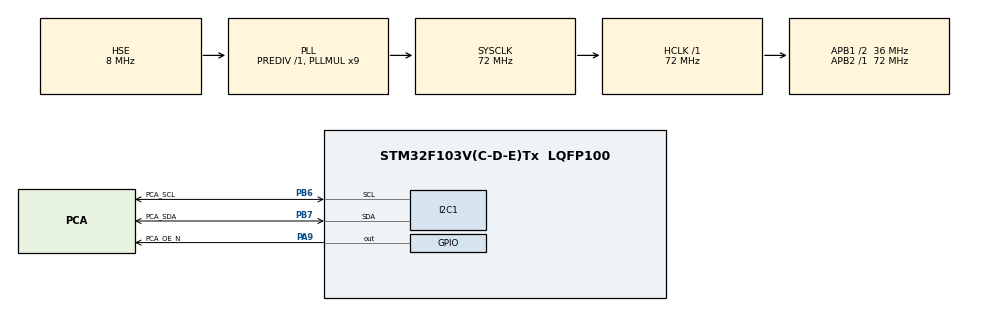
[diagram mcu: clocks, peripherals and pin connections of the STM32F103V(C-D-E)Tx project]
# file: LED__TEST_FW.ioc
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FREERTOS.BinarySemaphores01=allowRainbowSem,Dynamic,NULL
FREERTOS.Tasks01=initialSequence,0,256,initialSequenceTask,Default,NULL,Dynamic,NULL,NULL;rainbowTaskHand,-3,256,rainbowLoopTask,Default,NULL,Dynamic,NULL,NULL
FREERTOS.configUSE_NEWLIB_REENTRANT=1
Mcu.Family=STM32F1
Mcu.Name=STM32F103V(C-D-E)Tx
Mcu.Package=LQFP100
NVIC.I2C1_EV_IRQn=true\:5\:0\:false\:false\:true\:true\:true\:true\:true
NVIC.PriorityGroup=NVIC_PRIORITYGROUP_4
OSC_IN.Mode=HSE-External-Oscillator
OSC_IN.Signal=RCC_OSC_IN
OSC_OUT.Mode=HSE-External-Oscillator
OSC_OUT.Signal=RCC_OSC_OUT
PA13.Mode=Serial_Wire
PA13.Signal=SYS_JTMS-SWDIO
PA14.Mode=Serial_Wire
PA14.Signal=SYS_JTCK-SWCLK
PA9.GPIO_Label=PCA_OE_N
PA9.GPIO_PuPd=GPIO_PULLDOWN
PA9.Signal=GPIO_Output
PB6.GPIO_Label=PCA_SCL
PB6.Mode=I2C
PB6.Signal=I2C1_SCL
PB7.GPIO_Label=PCA_SDA
PB7.Mode=I2C
PB7.Signal=I2C1_SDA
ProjectManager.HeapSize=0x200
ProjectManager.StackSize=0x400
ProjectManager.TargetToolchain=STM32CubeIDE
RCC.AHBFreq_Value=72000000
RCC.APB1CLKDivider=RCC_HCLK_DIV2
RCC.APB1Freq_Value=36000000
RCC.APB1TimFreq_Value=72000000
RCC.APB2Freq_Value=72000000
RCC.APB2TimFreq_Value=72000000
RCC.HCLKFreq_Value=72000000
RCC.PLLMUL=RCC_PLL_MUL9
RCC.PLLSourceVirtual=RCC_PLLSOURCE_HSE
RCC.SYSCLKFreq_VALUE=72000000
RCC.SYSCLKSource=RCC_SYSCLKSOURCE_PLLCLK
RCC.USBFreq_Value=72000000
VP_FREERTOS_VS_CMSIS_V1.Mode=CMSIS_V1
board=custom

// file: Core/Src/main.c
/* USER CODE BEGIN Header */
/**
  ******************************************************************************
  * @file           : main.c
  * @brief          : Main program body
  ******************************************************************************
  * @attention
  *
  * Copyright (c) 2023 STMicroelectronics.
  * All rights reserved.
  *
  * This software is licensed under terms that can be found in the LICENSE file
  * in the root directory of this software component.
  * If no LICENSE file comes with this software, it is provided AS-IS.
  *
  ******************************************************************************
  */
/* USER CODE END Header */
#include "main.h"
#include "cmsis_os.h"
#include "i2c.h"
#include "gpio.h"

void SystemClock_Config(void);
void MX_FREERTOS_Init(void);

int main(void)
{

  /* MCU Configuration--------------------------------------------------------*/

  /* Reset of all peripherals, Initializes the Flash interface and the Systick. */
  HAL_Init();

  /* Configure the system clock */
  SystemClock_Config();

  /* Initialize all configured peripherals */
  MX_GPIO_Init();
  MX_I2C1_Init();

  /* Call init function for freertos objects (in freertos.c) */
  MX_FREERTOS_Init();

  /* Start scheduler */
  osKernelStart();

  /* We should never get here as control is now taken by the scheduler */
  /* Infinite loop */
  while (1)
  {

  }
}

void SystemClock_Config(void)
{
  RCC_OscInitTypeDef RCC_OscInitStruct = {0};
  RCC_ClkInitTypeDef RCC_ClkInitStruct = {0};

  /** Initializes the RCC Oscillators according to the specified parameters
  * in the RCC_OscInitTypeDef structure.
  */
  RCC_OscInitStruct.OscillatorType = RCC_OSCILLATORTYPE_HSE;
  RCC_OscInitStruct.HSEState = RCC_HSE_ON;
  RCC_OscInitStruct.HSEPredivValue = RCC_HSE_PREDIV_DIV1;
  RCC_OscInitStruct.HSIState = RCC_HSI_ON;
  RCC_OscInitStruct.PLL.PLLState = RCC_PLL_ON;
  RCC_OscInitStruct.PLL.PLLSource = RCC_PLLSOURCE_HSE;
  RCC_OscInitStruct.PLL.PLLMUL = RCC_PLL_MUL9;
  if (HAL_RCC_OscConfig(&RCC_OscInitStruct) != HAL_OK)
  {
    Error_Handler();
  }

  /** Initializes the CPU, AHB and APB buses clocks
  */
  RCC_ClkInitStruct.ClockType = RCC_CLOCKTYPE_HCLK|RCC_CLOCKTYPE_SYSCLK
                              |RCC_CLOCKTYPE_PCLK1|RCC_CLOCKTYPE_PCLK2;
  RCC_ClkInitStruct.SYSCLKSource = RCC_SYSCLKSOURCE_PLLCLK;
  RCC_ClkInitStruct.AHBCLKDivider = RCC_SYSCLK_DIV1;
  RCC_ClkInitStruct.APB1CLKDivider = RCC_HCLK_DIV2;
  RCC_ClkInitStruct.APB2CLKDivider = RCC_HCLK_DIV1;

  if (HAL_RCC_ClockConfig(&RCC_ClkInitStruct, FLASH_LATENCY_2) != HAL_OK)
  {
    Error_Handler();
  }
}

void Error_Handler(void)
{
  __disable_irq();
  while (1)
  {
  }
}

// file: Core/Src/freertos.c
/* USER CODE BEGIN Header */
/**
  ******************************************************************************
  * File Name          : freertos.c
  * Description        : Code for freertos applications
  ******************************************************************************
  * @attention
  *
  * Copyright (c) 2023 STMicroelectronics.
  * All rights reserved.
  *
  * This software is licensed under terms that can be found in the LICENSE file
  * in the root directory of this software component.
  * If no LICENSE file comes with this software, it is provided AS-IS.
  *
  ******************************************************************************
  */
/* USER CODE END Header */

#include "FreeRTOS.h"
#include "task.h"
#include "main.h"
#include "cmsis_os.h"

/* USER CODE BEGIN Includes */

#include "hw/pca9633.h"
#include "app/app.h"
#include "i2c.h"

/* USER CODE END Includes */

osThreadId initialSequenceHandle;
osThreadId rainbowTaskHandHandle;
osSemaphoreId allowRainbowSemHandle;

void initialSequenceTask(void const * argument);
void rainbowLoopTask(void const * argument);

void MX_FREERTOS_Init(void); /* (MISRA C 2004 rule 8.1) */

/* GetIdleTaskMemory prototype (linked to static allocation support) */
void vApplicationGetIdleTaskMemory( StaticTask_t **ppxIdleTaskTCBBuffer, StackType_t **ppxIdleTaskStackBuffer, uint32_t *pulIdleTaskStackSize );

/* USER CODE BEGIN GET_IDLE_TASK_MEMORY */
static StaticTask_t xIdleTaskTCBBuffer;
static StackType_t xIdleStack[configMINIMAL_STACK_SIZE];

void vApplicationGetIdleTaskMemory( StaticTask_t **ppxIdleTaskTCBBuffer, StackType_t **ppxIdleTaskStackBuffer, uint32_t *pulIdleTaskStackSize )
{
  *ppxIdleTaskTCBBuffer = &xIdleTaskTCBBuffer;
  *ppxIdleTaskStackBuffer = &xIdleStack[0];
  *pulIdleTaskStackSize = configMINIMAL_STACK_SIZE;
  /* place for user code */
}
/* USER CODE END GET_IDLE_TASK_MEMORY */

void MX_FREERTOS_Init(void) {

  /* Create the semaphores(s) */
  /* definition and creation of allowRainbowSem */
  osSemaphoreDef(allowRainbowSem);
  allowRainbowSemHandle = osSemaphoreCreate(osSemaphore(allowRainbowSem), 1);

  /* USER CODE BEGIN RTOS_SEMAPHORES */
  /* add semaphores, ... */

  // take semaphore, so rainbow task is blocked
  osSemaphoreWait(allowRainbowSemHandle, osWaitForever);

  /* USER CODE END RTOS_SEMAPHORES */

  /* Create the thread(s) */
  /* definition and creation of initialSequence */
  osThreadDef(initialSequence, initialSequenceTask, osPriorityNormal, 0, 256);
  initialSequenceHandle = osThreadCreate(osThread(initialSequence), NULL);

  /* definition and creation of rainbowTaskHand */
  osThreadDef(rainbowTaskHand, rainbowLoopTask, osPriorityIdle, 0, 256);
  rainbowTaskHandHandle = osThreadCreate(osThread(rainbowTaskHand), NULL);

}

void initialSequenceTask(void const * argument)
{
  /* USER CODE BEGIN initialSequenceTask */

	uint8_t seq_cnt = 0;

	// initialize spi device
	PCA9633_Init(&hi2c1);

  /* Infinite loop */
  for(;;)
  {
	  /**
	   * Execute sequence of events
	   */
	  if(seq_cnt == 0){
		  app_red_seq();
	  }else if(seq_cnt == 1){
		  app_green_seq();
	  }else if(seq_cnt == 2){
		  app_blue_seq();
	  }else if(seq_cnt == 3){
		  app_white_seq();
	  }else if(seq_cnt == 4){
		  app_mixed_red_wite_seq();
	  }else if(seq_cnt == 5){
		  app_lightness_seq();
	  }else{

		  /**
		   * No more start sequences so release semaphore
		   * to allow rainbow to shine
		   */
		  // release raibnow thread
		  osSemaphoreRelease(allowRainbowSemHandle);
		  // terminate task
		  osThreadTerminate(initialSequenceHandle);
		  break;
	  }
	  seq_cnt++;

    osDelay(10);
  }
  /* USER CODE END initialSequenceTask */
}

void rainbowLoopTask(void const * argument)
{
  /* USER CODE BEGIN rainbowLoopTask */
  /* Infinite loop */

	// wait for semaphore
	if (osSemaphoreWait(allowRainbowSemHandle, osWaitForever) == osOK) {

	  for(;;)
	  {
		  app_rainbow_gen();
	  }
	}
  /* USER CODE END rainbowLoopTask */
}
